# ESP32-P4 register map
Vendor: ESPRESSIF SYSTEMS (SHANGHAI) CO., LTD.; Series: ESP32 P-Series; File version: 3
CPU: RV32IMAFC r0p0, little endian, no MPU, FPU, 0 interrupt priority bits
Address unit: 32 bits
Registers are 32-bit, read-write, reset 0x0 unless marked. A register's access mark holds for its fields unless they carry their own. Offsets are from the block's base; [hi:lo] are bit positions; {n}, {i} and the like mark numbered series; 'fields as' and 'values as' point back to an identical list.

## LP_I2C_ANA_MST — LP_I2C_ANA_MST Peripheral
Base 0x50124000
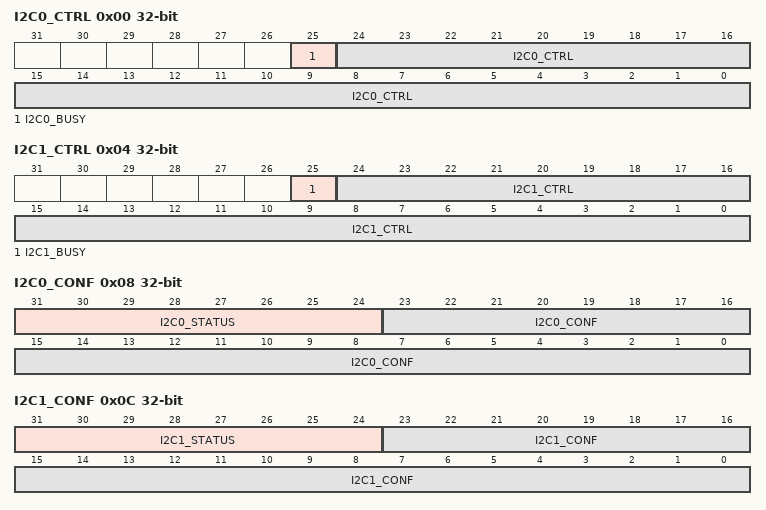
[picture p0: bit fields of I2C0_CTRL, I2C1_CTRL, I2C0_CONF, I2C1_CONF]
0x00 I2C0_CTRL access per field — need des
  [25] I2C0_BUSY ro — need des
  [24:0] I2C0_CTRL rw — need des
0x04 I2C1_CTRL access per field — need des
  [25] I2C1_BUSY ro — need des
  [24:0] I2C1_CTRL rw — need des
0x08 I2C0_CONF access per field — need des
  [31:24] I2C0_STATUS ro — need des
  [23:0] I2C0_CONF rw — need des
0x0C I2C1_CONF access per field — need des
  [31:24] I2C1_STATUS ro — need des
  [23:0] I2C1_CONF rw — need des
0x10 I2C_BURST_CONF — need des
  [31:0] I2C_MST_BURST_CTRL
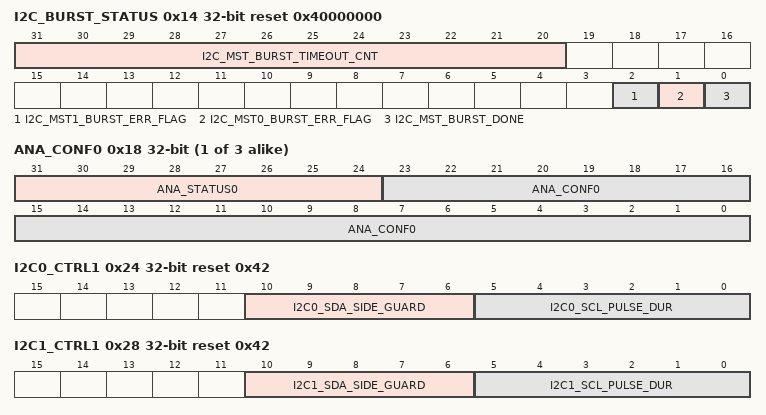
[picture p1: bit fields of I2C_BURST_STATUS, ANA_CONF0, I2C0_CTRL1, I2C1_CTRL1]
0x14 I2C_BURST_STATUS access per field reset 0x40000000 — need des
  [31:20] I2C_MST_BURST_TIMEOUT_CNT rw — need des
  [2] I2C_MST1_BURST_ERR_FLAG ro — need des
  [1] I2C_MST0_BURST_ERR_FLAG ro — need des
  [0] I2C_MST_BURST_DONE ro — need des
{0x18+4i} ANA_CONF{i} access per field (i=0..2) — need des
  [31:24] ANA_STATUS{i} ro — need des
  [23:0] ANA_CONF{i} rw — need des
0x24 I2C0_CTRL1 reset 0x42 — need des
  [10:6] I2C0_SDA_SIDE_GUARD — need des
  [5:0] I2C0_SCL_PULSE_DUR — need des
0x28 I2C1_CTRL1 reset 0x42 — need des
  [10:6] I2C1_SDA_SIDE_GUARD — need des
  [5:0] I2C1_SCL_PULSE_DUR — need des
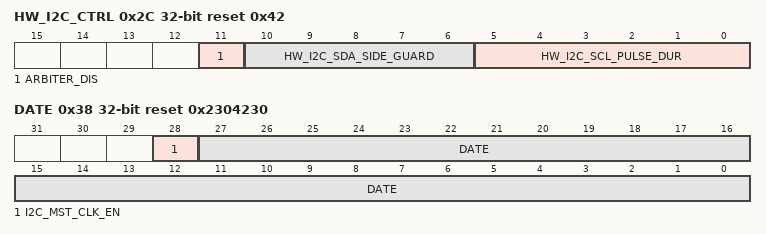
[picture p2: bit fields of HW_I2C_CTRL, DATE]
0x2C HW_I2C_CTRL reset 0x42 — need des
  [11] ARBITER_DIS — need des
  [10:6] HW_I2C_SDA_SIDE_GUARD — need des
  [5:0] HW_I2C_SCL_PULSE_DUR — need des
0x30 NOUSE — need des
  [31:0] I2C_MST_NOUSE
0x34 CLK160M — need des
  [0] CLK_I2C_MST_SEL_160M
0x38 DATE reset 0x2304230 — need des
  [28] I2C_MST_CLK_EN — need des
  [27:0] DATE — need des

## USB_HS
Base 0x50000000
Same registers: USB_FS 0x50040000, I2S1 0x500C7000, I2S2 0x500C8000
0x00 DUMMY access not given

## IOMUX_MSPI_PIN — IOMUX_MSPI_PIN Peripheral
Base 0x500E1200
0x00 CLK_EN0 reset 0x1 — apb registers auto clock gating reg
  [0] REG_CLK_EN — 1: auto clock gating on 0: auto clock gating off
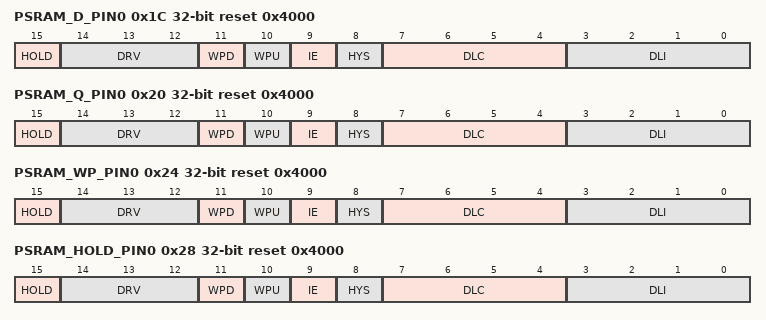
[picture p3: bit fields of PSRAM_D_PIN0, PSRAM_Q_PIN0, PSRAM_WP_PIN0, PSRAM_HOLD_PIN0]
0x1C PSRAM_D_PIN0 reset 0x4000 — IOMUX_MSPI_PIN_PSRAM_D_PIN0_REG
  [15] HOLD — psram d hold
  [14:12] DRV — psram d drv
  [11] WPD — psram d wpd
  [10] WPU — psram d wpu
  [9] IE — Reserved
  [8] HYS — psram d sl
  [7:4] DLC — psram d dlc
  [3:0] DLI — psram d dli
0x20 PSRAM_Q_PIN0 reset 0x4000 — IOMUX_MSPI_PIN_PSRAM_D_PIN0_REG
  fields as PSRAM_D_PIN0
0x24 PSRAM_WP_PIN0 reset 0x4000 — IOMUX_MSPI_PIN_PSRAM_D_PIN0_REG
  fields as PSRAM_D_PIN0
0x28 PSRAM_HOLD_PIN0 reset 0x4000 — IOMUX_MSPI_PIN_PSRAM_D_PIN0_REG
  fields as PSRAM_D_PIN0
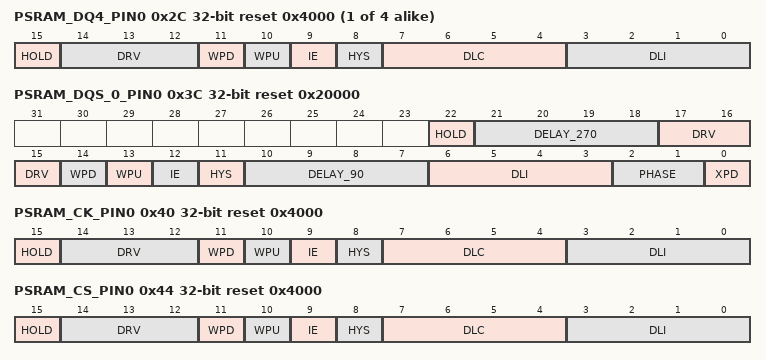
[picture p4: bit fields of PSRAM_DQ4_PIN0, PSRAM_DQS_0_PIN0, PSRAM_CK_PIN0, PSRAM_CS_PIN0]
{0x1C+4i} PSRAM_DQ{i}_PIN0 reset 0x4000 (i=4..7) — IOMUX_MSPI_PIN_PSRAM_D_PIN0_REG
  fields as PSRAM_D_PIN0
0x3C PSRAM_DQS_0_PIN0 reset 0x20000 — IOMUX_MSPI_PIN_PSRAM_D_PIN0_REG
  [22] HOLD — psram dqs hold
  [21:18] DELAY_270 — psram dqs0 delay 270
  [17:15] DRV — psram dqs0 drv
  [14] WPD — psram dqs0 wpd
  [13] WPU — psram dqs0 wpu
  [12] IE — Reserved
  [11] HYS — psram dqs0 sl
  [10:7] DELAY_90 — psram dqs0 delay 90
  [6:3] DLI — psram dqs0 dli
  [2:1] PHASE — psram dqs0 phase
  [0] XPD — psram xpd dqs0
0x40 PSRAM_CK_PIN0 reset 0x4000 — IOMUX_MSPI_PIN_PSRAM_D_PIN0_REG
  fields as PSRAM_D_PIN0
0x44 PSRAM_CS_PIN0 reset 0x4000 — IOMUX_MSPI_PIN_PSRAM_D_PIN0_REG
  fields as PSRAM_D_PIN0
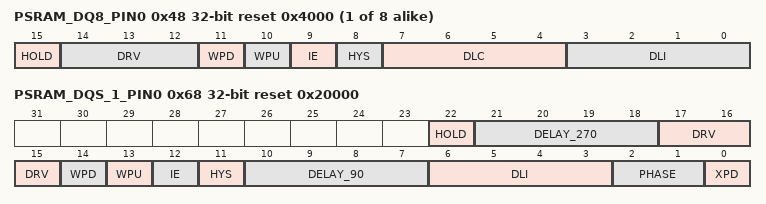
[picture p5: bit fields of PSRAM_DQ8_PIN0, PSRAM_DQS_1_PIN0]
{0x28+4i} PSRAM_DQ{i}_PIN0 reset 0x4000 (i=8..15) — IOMUX_MSPI_PIN_PSRAM_D_PIN0_REG
  fields as PSRAM_D_PIN0
0x68 PSRAM_DQS_1_PIN0 reset 0x20000 — IOMUX_MSPI_PIN_PSRAM_D_PIN0_REG
  fields as PSRAM_DQS_0_PIN0

## INTERRUPT_CORE0 — Interrupt Controller (Core 0)
Base 0x500D6000
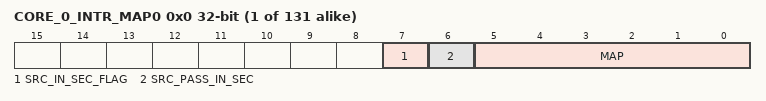
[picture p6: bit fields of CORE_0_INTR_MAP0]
{0x0+4i} CORE_0_INTR_MAP{i} (i=0..130)
  [7] SRC_IN_SEC_FLAG, [6] SRC_PASS_IN_SEC, [5:0] MAP
{0x200+4i} CORE_0_INTR_STATUS{i} (i=0..3) ro
  [31:0] CORE0_INTR_STATUS_0
0x210 CLOCK_GATE reset 0x1
  [0] CORE0_REG_CLK_EN
0x220 CORE_0_INTR_STATUS4 ro
  [31:0] CORE0_INTR_STATUS_4
0x228 INTR_SIG_IDX_ASSERT_IN_SEC
  [5:0] CORE0_INTR_SIG_IDX_ASSERT_IN_SEC
0x22C INTR_SEC_STATUS ro
  [31:0] CORE0_INTR_SEC_STATUS
{0x230+4i} INTR_SRC_PASS_IN_SEC_STATUS_{i} ro (i=0..4)
  [31:0] CORE0_INTR_SRC_PASS_IN_SEC_STATUS_{i}
0x3FC INTERRUPT_REG_DATE reset 0x2502280
  [27:0] CORE0_INTERRUPT_REG_DATE
